# MCXN947_cm33_core0 register map
Vendor: nxp.com; File version: 1.0
CPU: CM33 r2p0, little endian, MPU, FPU, VTOR, 3 interrupt priority bits
Registers are 32-bit, read-write, reset 0x0 unless marked. A register's access mark holds for its fields unless they carry their own. Offsets are from the block's base; [hi:lo] are bit positions; {n}, {i} and the like mark numbered series; 'fields as' and 'values as' point back to an identical list.

## ENET0 (part 2 of 2) — ENET
Base 0x40100000
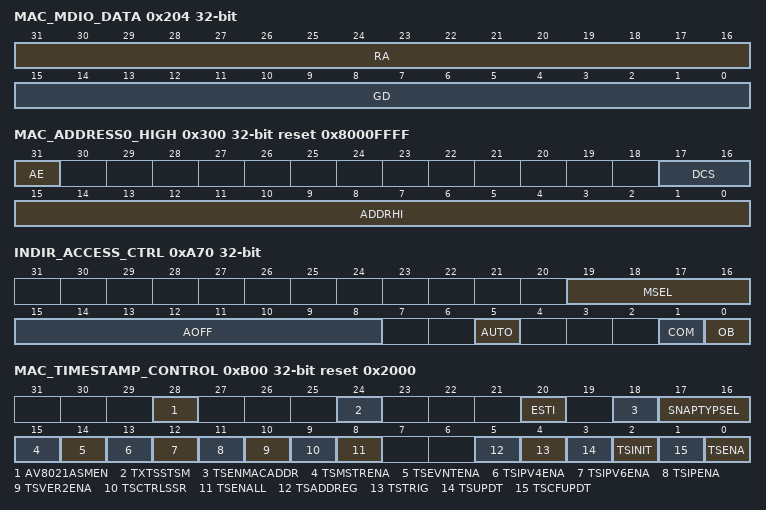
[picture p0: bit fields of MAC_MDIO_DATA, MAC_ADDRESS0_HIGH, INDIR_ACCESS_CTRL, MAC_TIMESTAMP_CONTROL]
0x204 MAC_MDIO_DATA
  [31:16] RA — Register Address
  [15:0] GD — GMII Data
0x230 MAC_CSR_SW_CTRL — CSR Software Control
  [0] RCWE — Register Clear on Write 1 Enable
    0=DISABLE (Register Clear on Write 1 is disabled); 1=ENABLE (Register Clear on Write 1 is enabled)
0x300 MAC_ADDRESS0_HIGH reset 0x8000FFFF
  [31] AE ro — Address Enable
    0=DISABLE (INVALID : This bit must be always set to 1); 1=ENABLE (This bit is always set to 1)
  [17:16] DCS — DMA Channel Select
  [15:0] ADDRHI — MAC Address0[47:32]
0x304 MAC_ADDRESS0_LOW reset 0xFFFFFFFF
  [31:0] ADDRLO — MAC Address0[31:0]
0xA70 INDIR_ACCESS_CTRL — Indirect Access Control
  [19:16] MSEL — Mode Select
  [15:8] AOFF — Address Offset
  [5] AUTO — Auto increment
  [1] COM — Command type
    0=WRITE (Write operation); 1=READ (Read operation)
  [0] OB — Operation Busy.
0xA74 INDIR_ACCESS_DATA — Indirect Access Data
  [31:0] DATA — This field contains data to read/write for Indirect address access associated with MAC_Indir_Access_Ctrl
0xB00 MAC_TIMESTAMP_CONTROL reset 0x2000 — Timestamp Control
  [28] AV8021ASMEN — AV 802.
    0=DISABLE (AV 802.1AS Mode is disabled); 1=ENABLE (AV 802.1AS Mode is enabled)
  [24] TXTSSTSM — Transmit Timestamp Status Mode
    0=DISABLE (Transmit Timestamp Status Mode is disabled); 1=ENABLE (Transmit Timestamp Status Mode is enabled)
  [20] ESTI — External System Time Input
    0=DISABLE (External System Time Input is disabled); 1=ENABLE (External System Time Input is enabled)
  [18] TSENMACADDR — Enable MAC Address for PTP Packet Filtering
    0=DISABLE (MAC Address for PTP Packet Filtering is disabled); 1=ENABLE (MAC Address for PTP Packet Filtering is enabled)
  [17:16] SNAPTYPSEL — Select PTP packets for Taking Snapshots
  [15] TSMSTRENA — Enable Snapshot for Messages Relevant to Master
    0=DISABLE (Snapshot for Messages Relevant to Master is disabled); 1=ENABLE (Snapshot for Messages Relevant to Master is enabled)
  [14] TSEVNTENA — Enable Timestamp Snapshot for Event Messages
    0=DISABLE (Timestamp Snapshot for Event Messages is disabled); 1=ENABLE (Timestamp Snapshot for Event Messages is enabled)
  [13] TSIPV4ENA — Enable Processing of PTP Packets Sent over IPv4-UDP
    0=DISABLE (Processing of PTP Packets Sent over IPv4-UDP is disabled); 1=ENABLE (Processing of PTP Packets Sent over IPv4-UDP is enabled)
  [12] TSIPV6ENA — Enable Processing of PTP Packets Sent over IPv6-UDP
    0=DISABLE (Processing of PTP Packets Sent over IPv6-UDP is disabled); 1=ENABLE (Processing of PTP Packets Sent over IPv6-UDP is enabled)
  [11] TSIPENA — Enable Processing of PTP over Ethernet Packets
    0=DISABLE (Processing of PTP over Ethernet Packets is disabled); 1=ENABLE (Processing of PTP over Ethernet Packets is enabled)
  [10] TSVER2ENA — Enable PTP Packet Processing for Version 2 Format
    0=DISABLE (PTP Packet Processing for Version 2 Format is disabled); 1=ENABLE (PTP Packet Processing for Version 2 Format is enabled)
  [9] TSCTRLSSR — Timestamp Digital or Binary Rollover Control
    0=DISABLE (Timestamp Digital or Binary Rollover Control is disabled); 1=ENABLE (Timestamp Digital or Binary Rollover Control is enabled)
  [8] TSENALL — Enable Timestamp for All Packets
    0=DISABLE (Timestamp for All Packets disabled); 1=ENABLE (Timestamp for All Packets enabled)
  [5] TSADDREG — Update Addend Register
    0=DISABLE (Addend Register is not updated); 1=ENABLE (Addend Register is updated)
  [4] TSTRIG — Enable Timestamp Interrupt Trigger
    0=DISABLE (Timestamp Interrupt Trigger is not enabled); 1=ENABLE (Timestamp Interrupt Trigger is enabled)
  [3] TSUPDT — Update Timestamp
    0=DISABLE (Timestamp is not updated); 1=ENABLE (Timestamp is updated)
  [2] TSINIT — Initialize Timestamp
    0=DISABLE (Timestamp is not initialized); 1=ENABLE (Timestamp is initialized)
  [1] TSCFUPDT — Fine or Coarse Timestamp Update
    0=COARSE (Coarse method is used to update system timestamp); 1=FINE (Fine method is used to update system timestamp)
  [0] TSENA — Enable Timestamp
    0=DISABLE (Timestamp is disabled); 1=ENABLE (Timestamp is enabled)
0xB04 MAC_SUB_SECOND_INCREMENT — Subsecond Increment
  [23:16] SNSINC — Sub-nanosecond Increment Value
0xB08 MAC_SYSTEM_TIME_SECONDS ro — System Time Seconds
  [31:0] TSS — Timestamp Second
0xB0C MAC_SYSTEM_TIME_NANOSECONDS ro — System Time Nanoseconds
  [30:0] TSSS — Timestamp Sub Seconds
0xB10 MAC_SYSTEM_TIME_SECONDS_UPDATE — System Time Seconds Update
  [31:0] TSS — Timestamp Seconds
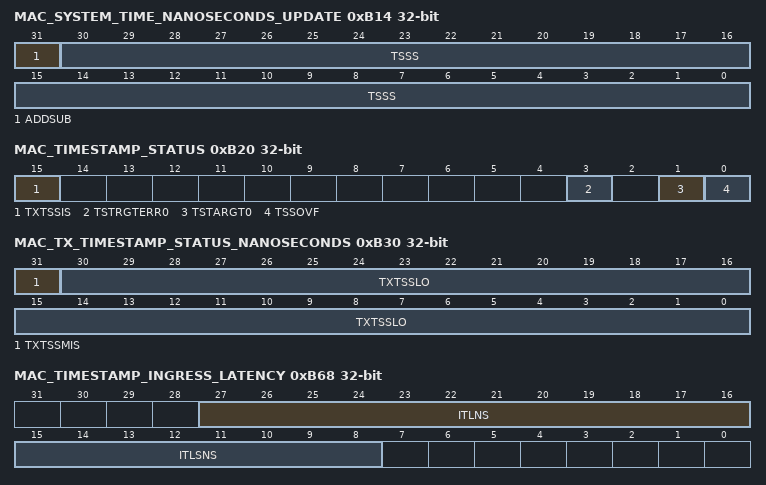
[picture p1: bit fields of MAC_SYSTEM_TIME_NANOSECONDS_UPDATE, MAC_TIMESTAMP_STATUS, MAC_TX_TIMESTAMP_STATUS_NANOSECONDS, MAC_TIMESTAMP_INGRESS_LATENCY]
0xB14 MAC_SYSTEM_TIME_NANOSECONDS_UPDATE — System Time Nanoseconds Update
  [31] ADDSUB — Add or Subtract Time
    0=ADD (Add time); 1=SUB (Subtract time)
  [30:0] TSSS — Timestamp Sub Seconds
0xB18 MAC_TIMESTAMP_ADDEND — Timestamp Addend
  [31:0] TSAR — Timestamp Addend Register
0xB20 MAC_TIMESTAMP_STATUS ro — Timestamp Status
  [15] TXTSSIS — Tx Timestamp Status Interrupt Status
    0=INACTIVE (Tx Timestamp Status Interrupt status not detected); 1=ACTIVE (Tx Timestamp Status Interrupt status detected)
  [3] TSTRGTERR0 — Timestamp Target Time Error
    0=INACTIVE (Timestamp Target Time Error status not detected); 1=ACTIVE (Timestamp Target Time Error status detected)
  [1] TSTARGT0 — Timestamp Target Time Reached
    0=INACTIVE (Timestamp Target Time Reached status not detected); 1=ACTIVE (Timestamp Target Time Reached status detected)
  [0] TSSOVF — Timestamp Seconds Overflow
    0=INACTIVE (Timestamp Seconds Overflow status not detected); 1=ACTIVE (Timestamp Seconds Overflow status detected)
0xB30 MAC_TX_TIMESTAMP_STATUS_NANOSECONDS ro — Transmit Timestamp Status Nanoseconds
  [31] TXTSSMIS
    0=INACTIVE (Transmit Timestamp Status Missed status not detected); 1=ACTIVE (Transmit Timestamp Status Missed status detected)
  [30:0] TXTSSLO — Transmit Timestamp Status Low
0xB34 MAC_TX_TIMESTAMP_STATUS_SECONDS ro — Transmit Timestamp Status Seconds
  [31:0] TXTSSHI — Transmit Timestamp Status High
0xB58 MAC_TIMESTAMP_INGRESS_CORR_NANOSECOND — Timestamp Ingress Correction Nanosecond
  [31:0] TSIC — Timestamp Ingress Correction
0xB5C MAC_TIMESTAMP_EGRESS_CORR_NANOSECOND — Timestamp Egress Correction Nanosecond
  [31:0] TSEC — Timestamp Egress Correction
0xB68 MAC_TIMESTAMP_INGRESS_LATENCY ro — Timestamp Ingress Latency
  [27:16] ITLNS, [15:8] ITLSNS
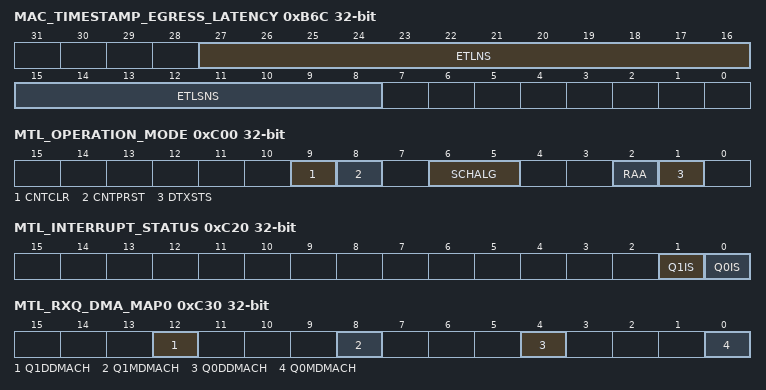
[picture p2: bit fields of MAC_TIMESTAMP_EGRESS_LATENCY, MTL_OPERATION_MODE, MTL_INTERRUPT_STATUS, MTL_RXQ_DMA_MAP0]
0xB6C MAC_TIMESTAMP_EGRESS_LATENCY ro — Timestamp Egress Latency
  [27:16] ETLNS — Egress Timestamp Latency, in nanoseconds
  [15:8] ETLSNS — Egress Timestamp Latency, in sub-nanoseconds
0xB70 MAC_PPS_CONTROL — PPS Control
  [3:0] PPSCTRL_PPSCMD — PPS Output Frequency Control
0xB80 PPS0_TARGET_TIME_SECONDS
  [31:0] TSTRH0 — PPS Target Time Seconds Register
0xB84 PPS0_TARGET_TIME_NANOSECONDS
  [30:0] TTSL0 — Target Time Low for PPS Register
0xC00 MTL_OPERATION_MODE
  [9] CNTCLR — Counters Reset
    0=DISABLE (Counters are not reset); 1=ENABLE (All counters are reset)
  [8] CNTPRST — Counters Preset
    0=DISABLE (Counters Preset is disabled); 1=ENABLE (Counters Preset is enabled)
  [6:5] SCHALG — Tx Scheduling Algorithm
    0=WRR (WRR algorithm); 1=WFQ (WFQ algorithm when DCB feature is selected.Otherwise, Reserved); 2=DWRR (DWRR algorithm when DCB feature is selected.Otherwise, Reserved); 3=SP (Strict priority algorithm)
  [2] RAA — Receive Arbitration Algorithm
    0=SP (Strict priority (SP)); 1=WSP (Weighted Strict Priority (WSP))
  [1] DTXSTS — Drop Transmit Status
    0=DISABLE (Drop Transmit Status is disabled); 1=ENABLE (Drop Transmit Status is enabled)
0xC20 MTL_INTERRUPT_STATUS ro
  [1] Q1IS — Queue 1 Interrupt status
    0=INACTIVE (Queue 1 Interrupt status not detected); 1=ACTIVE (Queue 1 Interrupt status detected)
  [0] Q0IS — Queue 0 Interrupt status
    0=INACTIVE (Queue 0 Interrupt status not detected); 1=ACTIVE (Queue 0 Interrupt status detected)
0xC30 MTL_RXQ_DMA_MAP0 — Receive Queue and DMA Channel Mapping 0
  [12] Q1DDMACH — Queue 1 Enabled for DA-based DMA Channel Selection
    0=DISABLE (Queue 1 disabled for DA-based DMA Channel Selection); 1=ENABLE (Queue 1 enabled for DA-based DMA Channel Selection)
  [8] Q1MDMACH — Queue 1 Mapped to DMA Channel
  [4] Q0DDMACH — Queue 0 Enabled for DA-based DMA Channel Selection
    0=DISABLE (Queue 0 disabled for DA-based DMA Channel Selection); 1=ENABLE (Queue 0 enabled for DA-based DMA Channel Selection)
  [0] Q0MDMACH — Queue 0 Mapped to DMA Channel
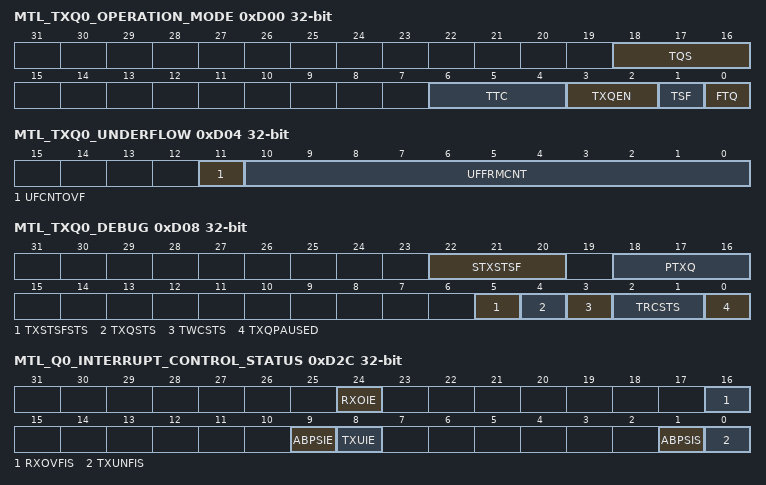
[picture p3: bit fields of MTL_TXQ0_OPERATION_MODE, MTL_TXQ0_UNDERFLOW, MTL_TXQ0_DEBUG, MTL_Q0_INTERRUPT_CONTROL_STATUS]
0xD00 MTL_TXQ0_OPERATION_MODE — Queue 0 Transmit Operation Mode
  [18:16] TQS — Transmit Queue Size
  [6:4] TTC — Transmit Threshold Control
    0=M_32BYTES (32); 1=M_64BYTES (64); 2=M_96BYTES (96); 3=M_128BYTES (128); 4=M_192BYTES (192); 5=M_256BYTES (256); 6=M_384BYTES (384); 7=M_512BYTES (512)
  [3:2] TXQEN — Transmit Queue Enable
    0=DISABLE (Not enabled); 1=EN_IF_AV (Enable in AV mode (Reserved in non-AV)); 2=ENABLE (Enabled)
  [1] TSF — Transmit Store and Forward
    0=DISABLE (Transmit Store and Forward is disabled); 1=ENABLE (Transmit Store and Forward is enabled)
  [0] FTQ — Flush Transmit Queue
    0=DISABLE (Flush Transmit Queue is disabled); 1=ENABLE (Flush Transmit Queue is enabled)
0xD04 MTL_TXQ0_UNDERFLOW ro — Queue 0 Underflow Counter
  [11] UFCNTOVF — Overflow Bit for Underflow Packet Counter
    0=INACTIVE (Overflow not detected for Underflow Packet Counter); 1=ACTIVE (Overflow detected for Underflow Packet Counter)
  [10:0] UFFRMCNT — Underflow Packet Counter
0xD08 MTL_TXQ0_DEBUG ro — Queue 0 Transmit Debug
  [22:20] STXSTSF — Number of Status Words in Tx Status FIFO of Queue
  [18:16] PTXQ — Number of Packets in the Transmit Queue
  [5] TXSTSFSTS — MTL Tx Status FIFO Full Status
    0=INACTIVE (MTL Tx Status FIFO Full status is not detected); 1=ACTIVE (MTL Tx Status FIFO Full status is detected)
  [4] TXQSTS — MTL Tx Queue Not Empty Status
    0=INACTIVE (MTL Tx Queue Not Empty status is not detected); 1=ACTIVE (MTL Tx Queue Not Empty status is detected)
  [3] TWCSTS — MTL Tx Queue Write Controller Status
    0=INACTIVE (MTL Tx Queue Write Controller status is not detected); 1=ACTIVE (MTL Tx Queue Write Controller status is detected)
  [2:1] TRCSTS — MTL Tx Queue Read Controller Status
    0=IDLE (Idle state); 1=READ (Read state (transferring data to the MAC transmitter)); 2=WAIT (Waiting for pending Tx Status from the MAC transmitter); 3=FLUSH (Flushing the Tx queue because of the Packet Abort request from the MAC)
  [0] TXQPAUSED — Transmit Queue in Pause
    0=INACTIVE (Transmit Queue in Pause status is not detected); 1=ACTIVE (Transmit Queue in Pause status is detected)
0xD14 MTL_TXQ0_ETS_STATUS ro — Queue 0 ETS Status
  [23:0] ABS — Average Bits per Slot
0xD18 MTL_TXQ0_QUANTUM_WEIGHT — Queue 0 Quantum or Weights
  [20:0] ISCQW — Quantum or Weights
0xD2C MTL_Q0_INTERRUPT_CONTROL_STATUS — Queue 0 Interrupt Control Status
  [24] RXOIE — Receive Queue Overflow Interrupt Enable
    0=DISABLE (Receive Queue Overflow Interrupt is disabled); 1=ENABLE (Receive Queue Overflow Interrupt is enabled)
  [16] RXOVFIS — Receive Queue Overflow Interrupt Status
    0=INACTIVE (Receive Queue Overflow Interrupt Status not detected); 1=ACTIVE (Receive Queue Overflow Interrupt Status detected)
  [9] ABPSIE — Average Bits Per Slot Interrupt Enable
    0=DISABLE (Average Bits Per Slot Interrupt is disabled); 1=ENABLE (Average Bits Per Slot Interrupt is enabled)
  [8] TXUIE — Transmit Queue Underflow Interrupt Enable
    0=DISABLE (Transmit Queue Underflow Interrupt Status is disabled); 1=ENABLE (Transmit Queue Underflow Interrupt Status is enabled)
  [1] ABPSIS — Average Bits Per Slot Interrupt Status
    0=INACTIVE (Average Bits Per Slot Interrupt Status not detected); 1=ACTIVE (Average Bits Per Slot Interrupt Status detected)
  [0] TXUNFIS — Transmit Queue Underflow Interrupt Status
    0=INACTIVE (Transmit Queue Underflow Interrupt Status not detected); 1=ACTIVE (Transmit Queue Underflow Interrupt Status detected)
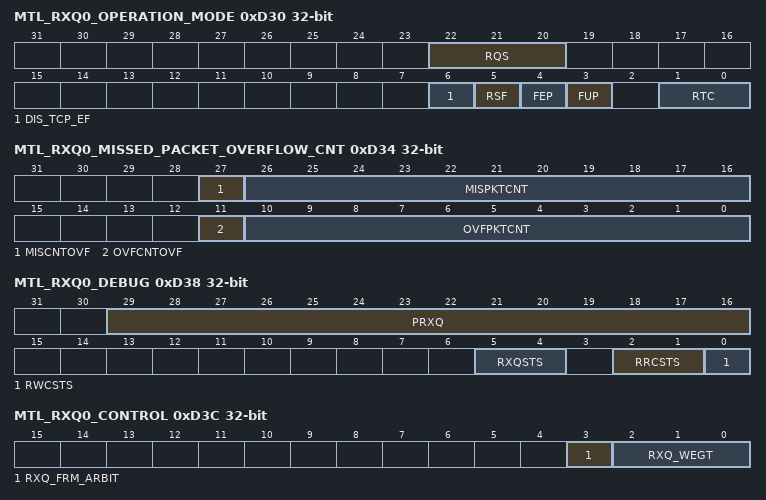
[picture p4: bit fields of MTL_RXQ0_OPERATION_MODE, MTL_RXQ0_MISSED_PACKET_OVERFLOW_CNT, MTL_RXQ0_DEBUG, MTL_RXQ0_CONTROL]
0xD30 MTL_RXQ0_OPERATION_MODE — Queue 0 Receive Operation Mode
  [22:20] RQS — Receive Queue Size
  [6] DIS_TCP_EF — Disable Dropping of TCP/IP Checksum Error Packets
    0=ENABLE (Dropping of TCP/IP Checksum Error Packets is enabled); 1=DISABLE (Dropping of TCP/IP Checksum Error Packets is disabled)
  [5] RSF — Receive Queue Store and Forward
    0=DISABLE (Receive Queue Store and Forward is disabled); 1=ENABLE (Receive Queue Store and Forward is enabled)
  [4] FEP — Forward Error Packets
    0=DISABLE (Forward Error Packets is disabled); 1=ENABLE (Forward Error Packets is enabled)
  [3] FUP — Forward Undersized Good Packets
    0=DISABLE (Forward Undersized Good Packets is disabled); 1=ENABLE (Forward Undersized Good Packets is enabled)
  [1:0] RTC — Receive Queue Threshold Control
    0=M_64BYTE (64); 1=M_32BYTE (32); 2=M_96BYTE (96); 3=M_128BYTE (128)
0xD34 MTL_RXQ0_MISSED_PACKET_OVERFLOW_CNT ro — Queue 0 Missed Packet and Overflow Counter
  [27] MISCNTOVF — Missed Packet Counter Overflow Bit
    0=INACTIVE (Missed Packet Counter overflow not detected); 1=ACTIVE (Missed Packet Counter overflow detected)
  [26:16] MISPKTCNT — Missed Packet Counter
  [11] OVFCNTOVF — Overflow Counter Overflow Bit
    0=INACTIVE (Overflow Counter overflow not detected); 1=ACTIVE (Overflow Counter overflow detected)
  [10:0] OVFPKTCNT — Overflow Packet Counter
0xD38 MTL_RXQ0_DEBUG ro — Queue 0 Receive Debug
  [29:16] PRXQ — Number of Packets in Receive Queue
  [5:4] RXQSTS — MTL Rx Queue Fill-Level Status
    0=EMPTY (Rx Queue empty); 1=BLW_THR (Rx Queue fill-level below flow-control deactivate threshold); 2=ABV_THR (Rx Queue fill-level above flow-control activate threshold); 3=FULL (Rx Queue full)
  [2:1] RRCSTS — MTL Rx Queue Read Controller State
    0=IDLE (Idle state); 1=READ_DATA (Reading packet data); 2=READ_STS (Reading packet status (or timestamp)); 3=FLUSH (Flushing the packet data and status)
  [0] RWCSTS — MTL Rx Queue Write Controller Active Status
    0=INACTIVE (MTL Rx Queue Write Controller Active Status not detected); 1=ACTIVE (MTL Rx Queue Write Controller Active Status detected)
0xD3C MTL_RXQ0_CONTROL — Queue 0 Receive Control
  [3] RXQ_FRM_ARBIT — Receive Queue Packet Arbitration
    0=DISABLE (Receive Queue Packet Arbitration is disabled); 1=ENABLE (Receive Queue Packet Arbitration is enabled)
  [2:0] RXQ_WEGT — Receive Queue Weight
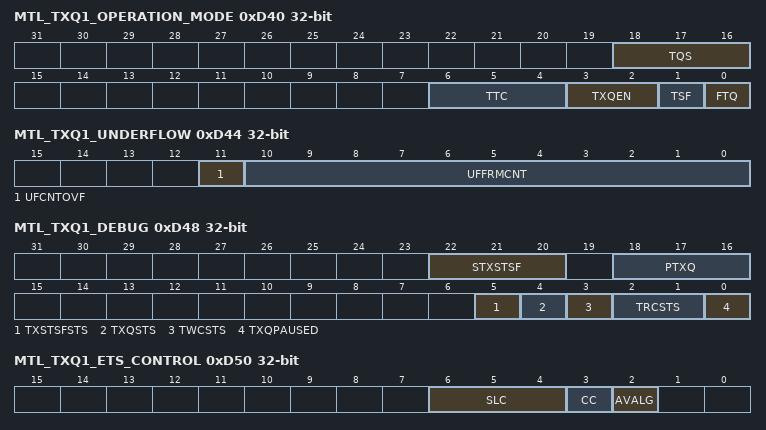
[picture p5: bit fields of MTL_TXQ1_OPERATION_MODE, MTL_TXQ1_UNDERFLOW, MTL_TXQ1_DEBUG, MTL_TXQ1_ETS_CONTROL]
0xD40 MTL_TXQ1_OPERATION_MODE — Queue 1 Transmit Operation Mode
  fields as MTL_TXQ0_OPERATION_MODE
0xD44 MTL_TXQ1_UNDERFLOW ro — Queue 1 Underflow Counter
  fields as MTL_TXQ0_UNDERFLOW
0xD48 MTL_TXQ1_DEBUG ro — Queue 1 Transmit Debug
  fields as MTL_TXQ0_DEBUG
0xD50 MTL_TXQ1_ETS_CONTROL — Queue 1 ETS Control
  [6:4] SLC — Slot Count
    0=M_1_SLOT (1 slot); 1=M_2_SLOT (2 slots); 2=M_4_SLOT (4 slots); 3=M_8_SLOT (8 slots); 4=M_16_SLOT (16 slots)
  [3] CC — Credit Control
    0=DISABLE (Credit Control is disabled); 1=ENABLE (Credit Control is enabled)
  [2] AVALG — AV Algorithm
    0=DISABLE (CBS Algorithm is disabled); 1=ENABLE (CBS Algorithm is enabled)
0xD54 MTL_TXQ1_ETS_STATUS ro — Queue 1 ETS Status
  [23:0] ABS — Average Bits per Slot
0xD58 MTL_TXQ1_QUANTUM_WEIGHT — Queue 1 idleSlopeCredit, Quantum or Weights
  [20:0] ISCQW — idleSlopeCredit, Quantum or Weights
0xD5C MTL_TXQ1_SENDSLOPECREDIT — Queue 1 sendSlopeCredit
  [13:0] SSC — sendSlopeCredit Value
0xD60 MTL_TXQ1_HICREDIT — Queue 1 hiCredit
  [28:0] HC — hiCredit Value
0xD64 MTL_TXQ1_LOCREDIT — Queue 1 loCredit
  [28:0] LC — loCredit Value
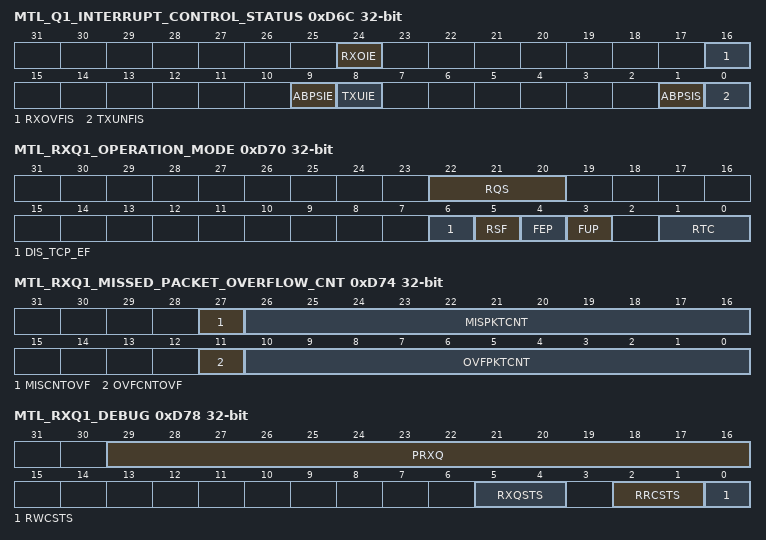
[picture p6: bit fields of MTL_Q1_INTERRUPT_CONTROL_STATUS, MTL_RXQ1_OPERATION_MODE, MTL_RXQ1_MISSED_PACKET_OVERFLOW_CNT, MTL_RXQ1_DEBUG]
0xD6C MTL_Q1_INTERRUPT_CONTROL_STATUS — Queue 1 Interrupt Control Status
  fields as MTL_Q0_INTERRUPT_CONTROL_STATUS
0xD70 MTL_RXQ1_OPERATION_MODE — Queue 1 Receive Operation Mode
  fields as MTL_RXQ0_OPERATION_MODE
0xD74 MTL_RXQ1_MISSED_PACKET_OVERFLOW_CNT ro — Queue 1 Missed Packet and Overflow Counter
  fields as MTL_RXQ0_MISSED_PACKET_OVERFLOW_CNT
0xD78 MTL_RXQ1_DEBUG ro — Queue 1 Receive Debug
  fields as MTL_RXQ0_DEBUG
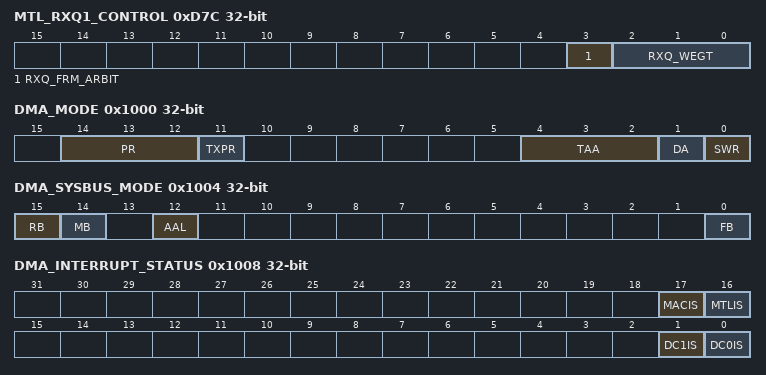
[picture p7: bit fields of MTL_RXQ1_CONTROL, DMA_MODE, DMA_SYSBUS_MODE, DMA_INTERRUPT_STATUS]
0xD7C MTL_RXQ1_CONTROL — Queue 1 Receive Control
  fields as MTL_RXQ0_CONTROL
0x1000 DMA_MODE — DMA Bus Mode
  [14:12] PR — Priority Ratio
    {v}=R_{v+1}_1 (The priority ratio is {v+1}:1) (v=0..7)
  [11] TXPR — Transmit Priority
    0=DISABLE (Transmit Priority is disabled); 1=ENABLE (Transmit Priority is enabled)
  [4:2] TAA — Transmit Arbitration Algorithm
    0=FP (Fixed priority); 1=WSP (Weighted Strict Priority (WSP)); 2=WRR (Weighted Round-Robin (WRR))
  [1] DA — DMA Tx or Rx Arbitration Scheme
    0=WRR (Weighted Round-Robin with Rx:Tx or Tx:Rx); 1=FP (Fixed Priority)
  [0] SWR — Software Reset
    0=DISABLE (Software Reset is disabled); 1=ENABLE (Software Reset is enabled)
0x1004 DMA_SYSBUS_MODE — DMA System Bus Mode
  [15] RB — Rebuild INCRx Burst
    0=DISABLE (Rebuild INCRx Burst is disabled); 1=ENABLE (Rebuild INCRx Burst is enabled)
  [14] MB — Mixed Burst
    0=DISABLE (Mixed Burst is disabled); 1=ENABLE (Mixed Burst is enabled)
  [12] AAL — Address-Aligned Beats
    0=DISABLE (Address-Aligned Beats is disabled); 1=ENABLE (Address-Aligned Beats is enabled)
  [0] FB — Fixed Burst Length
    0=DISABLE (Fixed Burst Length is disabled); 1=ENABLE (Fixed Burst Length is enabled)
0x1008 DMA_INTERRUPT_STATUS ro
  [17] MACIS — MAC Interrupt Status
    0=INACTIVE (MAC Interrupt Status not detected); 1=ACTIVE (MAC Interrupt Status detected)
  [16] MTLIS — MTL Interrupt Status
    0=INACTIVE (MTL Interrupt Status not detected); 1=ACTIVE (MTL Interrupt Status detected)
  [1] DC1IS — DMA Channel 1 Interrupt Status
    0=INACTIVE (DMA Channel 1 Interrupt Status not detected); 1=ACTIVE (DMA Channel 1 Interrupt Status detected)
  [0] DC0IS — DMA Channel 0 Interrupt Status
    0=INACTIVE (DMA Channel 0 Interrupt Status not detected); 1=ACTIVE (DMA Channel 0 Interrupt Status detected)
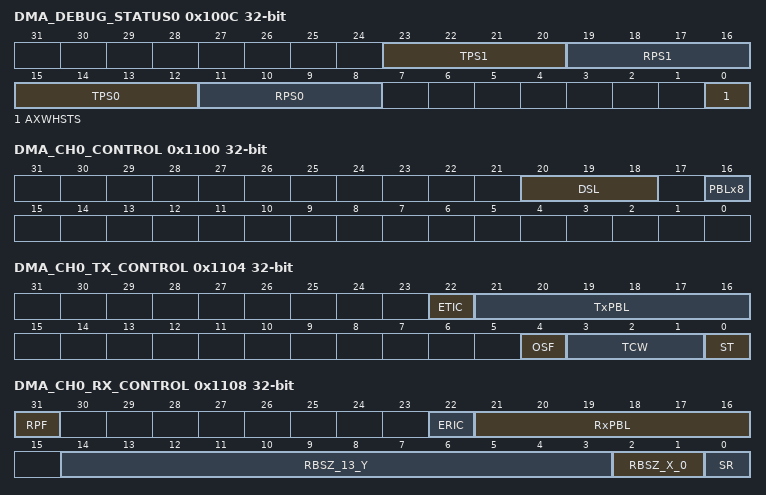
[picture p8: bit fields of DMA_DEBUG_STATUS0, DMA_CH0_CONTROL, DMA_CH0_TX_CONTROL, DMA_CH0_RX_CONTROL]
0x100C DMA_DEBUG_STATUS0 ro
  [23:20] TPS1 — DMA Channel 1 Transmit Process State
    0=STOP (Stopped (Reset or Stop Transmit Command issued)); 1=RUN_FTTD (Running (Fetching Tx Transfer Descriptor)); 2=RUN_WS (Running (Waiting for status)); 3=RUN_RDS (Running (Reading Data from system memory buffer and queuing it to the Tx buffer (Tx FIFO))); 4=TSTMP_WS (Timestamp write state); 6=SUSPND (Suspended (Tx Descriptor Unavailable or Tx Buffer Underflow)); 7=RUN_CTD (Running (Closing Tx Descriptor))
  [19:16] RPS1 — DMA Channel 1 Receive Process State
    0=STOP (Stopped (Reset or Stop Receive Command issued)); 1=RUN_FRTD (Running (Fetching Rx Transfer Descriptor)); 3=RUN_WRP (Running (Waiting for Rx packet)); 4=SUSPND (Suspended (Rx Descriptor Unavailable)); 5=RUN_CRD (Running (Closing the Rx Descriptor)); 6=TSTMP (Timestamp write state); 7=RUN_TRP (Running (Transferring the received packet data from the Rx buffer to the system memory))
  [15:12] TPS0 — DMA Channel 0 Transmit Process State
    values as TPS1
  [11:8] RPS0 — DMA Channel 0 Receive Process State
    values as RPS1
  [0] AXWHSTS — AHB Master Status
    0=INACTIVE (AXI Master Write Channel or AHB Master Status not detected); 1=ACTIVE (AXI Master Write Channel or AHB Master Status detected)
0x1100 DMA_CH0_CONTROL — DMA Channel 0 Control
  [20:18] DSL — Descriptor Skip Length
  [16] PBLx8 — 8xPBL mode
    0=DISABLE (8xPBL mode is disabled); 1=ENABLE (8xPBL mode is enabled)
0x1104 DMA_CH0_TX_CONTROL — DMA Channel 0 Transmit Control
  [22] ETIC — Early Transmit Interrupt Control
    0=DISABLE (Early Transmit Interrupt is disabled); 1=ENABLE (Early Transmit Interrupt is enabled)
  [21:16] TxPBL — Transmit Programmable Burst Length
  [4] OSF — Operate on Second Packet
    0=DISABLE (Operate on Second Packet disabled); 1=ENABLE (Operate on Second Packet enabled)
  [3:1] TCW — Transmit Channel Weight
  [0] ST — Start or Stop Transmission Command
    0=STOP (Stop Transmission Command); 1=START (Start Transmission Command)
0x1108 DMA_CH0_RX_CONTROL — DMA Channel 0 Receive Control
  [31] RPF — Rx Packet Flush.
    0=DISABLE (Rx Packet Flush is disabled); 1=ENABLE (Rx Packet Flush is enabled)
  [22] ERIC — Early Receive Interrupt Control
    0=DISABLE (Early Receive Interrupt is disabled); 1=ENABLE (Early Receive Interrupt is enabled)
  [21:16] RxPBL — Receive Programmable Burst Length
  [14:3] RBSZ_13_Y — Receive Buffer size High
  [2:1] RBSZ_X_0 ro — Receive Buffer size Low
  [0] SR — Start or Stop Receive
    0=STOP (Stop Receive); 1=START (Start Receive)
0x1114 DMA_CH0_TXDESC_LIST_ADDRESS — Channel 0 Tx Descriptor List Address register
  [31:2] TDESLA — Start of Transmit List
0x111C DMA_CH0_RXDESC_LIST_ADDRESS — Channel 0 Rx Descriptor List Address register
  [31:2] RDESLA — Start of Receive List
0x1120 DMA_CH0_TXDESC_TAIL_POINTER — Channel 0 Tx Descriptor Tail Pointer
  [31:2] TDTP — Transmit Descriptor Tail Pointer
0x1128 DMA_CH0_RXDESC_TAIL_POINTER — Channel 0 Rx Descriptor Tail Pointer
  [31:2] RDTP — Receive Descriptor Tail Pointer
0x112C DMA_CH0_TXDESC_RING_LENGTH — Channel 0 Tx Descriptor Ring Length
  [9:0] TDRL — Transmit Descriptor Ring Length
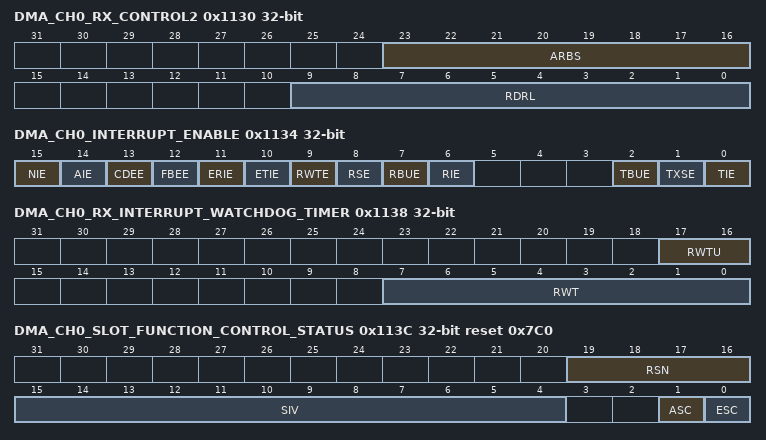
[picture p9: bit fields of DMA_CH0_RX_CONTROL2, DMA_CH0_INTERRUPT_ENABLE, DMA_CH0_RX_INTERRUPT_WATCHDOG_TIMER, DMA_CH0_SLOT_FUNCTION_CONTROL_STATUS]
0x1130 DMA_CH0_RX_CONTROL2 — Channeli Receive Control
  [23:16] ARBS — Alternate Receive Buffer Size
  [9:0] RDRL — Receive Descriptor Ring Length
0x1134 DMA_CH0_INTERRUPT_ENABLE — The Channeli Interrupt Enable register enables the interrupts reported by the Status register.
  [15] NIE — Normal Interrupt Summary Enable
    0=DISABLE (Normal Interrupt Summary is disabled); 1=ENABLE (Normal Interrupt Summary is enabled)
  [14] AIE — Abnormal Interrupt Summary Enable
    0=DISABLE (Abnormal Interrupt Summary is disabled); 1=ENABLE (Abnormal Interrupt Summary is enabled)
  [13] CDEE — Context Descriptor Error Enable
    0=DISABLE (Context Descriptor Error is disabled); 1=ENABLE (Context Descriptor Error is enabled)
  [12] FBEE — Fatal Bus Error Enable
    0=DISABLE (Fatal Bus Error is disabled); 1=ENABLE (Fatal Bus Error is enabled)
  [11] ERIE — Early Receive Interrupt Enable
    values as DMA_CH0_RX_CONTROL.ERIC
  [10] ETIE — Early Transmit Interrupt Enable
    values as DMA_CH0_TX_CONTROL.ETIC
  [9] RWTE — Receive Watchdog Timeout Enable
    0=DISABLE (Receive Watchdog Timeout is disabled); 1=ENABLE (Receive Watchdog Timeout is enabled)
  [8] RSE — Receive Stopped Enable
    0=DISABLE (Receive Stopped is disabled); 1=ENABLE (Receive Stopped is enabled)
  [7] RBUE — Receive Buffer Unavailable Enable
    0=DISABLE (Receive Buffer Unavailable is disabled); 1=ENABLE (Receive Buffer Unavailable is enabled)
  [6] RIE — Receive Interrupt Enable
    0=DISABLE (Receive Interrupt is disabled); 1=ENABLE (Receive Interrupt is enabled)
  [2] TBUE — Transmit Buffer Unavailable Enable
    0=DISABLE (Transmit Buffer Unavailable is disabled); 1=ENABLE (Transmit Buffer Unavailable is enabled)
  [1] TXSE — Transmit Stopped Enable
    0=DISABLE (Transmit Stopped is disabled); 1=ENABLE (Transmit Stopped is enabled)
  [0] TIE — Transmit Interrupt Enable
    0=DISABLE (Transmit Interrupt is disabled); 1=ENABLE (Transmit Interrupt is enabled)
0x1138 DMA_CH0_RX_INTERRUPT_WATCHDOG_TIMER — Channel 0 Receive Interrupt Watchdog Timer
  [17:16] RWTU — Receive Interrupt Watchdog Timer Count Units
  [7:0] RWT — Receive Interrupt Watchdog Timer Count
0x113C DMA_CH0_SLOT_FUNCTION_CONTROL_STATUS reset 0x7C0 — Channel 0 Slot Function Control and Status
  [19:16] RSN ro — Reference Slot Number
  [15:4] SIV — Slot Interval Value
  [1] ASC — Advance Slot Check
    0=DISABLE (Advance Slot Check is disabled); 1=ENABLE (Advance Slot Check is enabled)
  [0] ESC — Enable Slot Comparison
    0=DISABLE (Slot Comparison is disabled); 1=ENABLE (Slot Comparison is enabled)
0x1144 DMA_CH0_CURRENT_APP_TXDESC ro — Channel 0 Current Application Transmit Descriptor
  [31:0] CURTDESAPTR — Application Transmit Descriptor Address Pointer
0x114C DMA_CH0_CURRENT_APP_RXDESC ro — Channel 0 Current Application Receive Descriptor
  [31:0] CURRDESAPTR — Application Receive Descriptor Address Pointer
0x1154 DMA_CH0_CURRENT_APP_TXBUFFER ro — Channel 0 Current Application Transmit Buffer Address
  [31:0] CURTBUFAPTR — Application Transmit Buffer Address Pointer
0x115C DMA_CH0_CURRENT_APP_RXBUFFER ro — Channel 0 Current Application Receive Buffer Address
  [31:0] CURRBUFAPTR — Application Receive Buffer Address Pointer
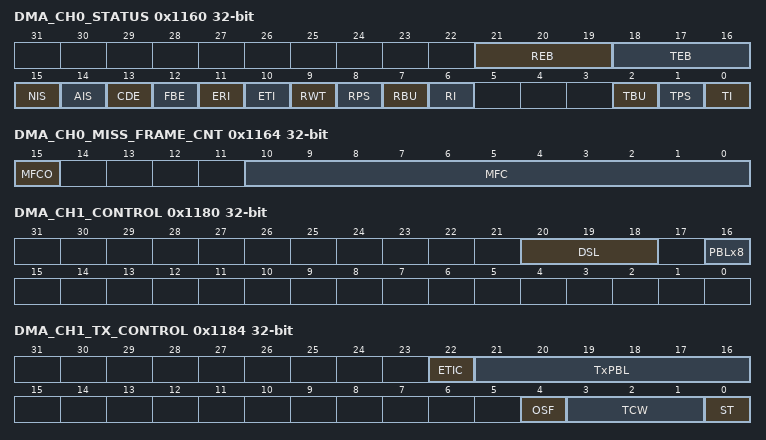
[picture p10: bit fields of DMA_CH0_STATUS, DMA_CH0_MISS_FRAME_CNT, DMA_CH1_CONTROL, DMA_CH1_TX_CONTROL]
0x1160 DMA_CH0_STATUS — DMA Channel 0 Status
  [21:19] REB ro — Rx DMA Error Bits
  [18:16] TEB ro — Tx DMA Error Bits
  [15] NIS — Normal Interrupt Summary
    0=INACTIVE (Normal Interrupt Summary status not detected); 1=ACTIVE (Normal Interrupt Summary status detected)
  [14] AIS — Abnormal Interrupt Summary
    0=INACTIVE (Abnormal Interrupt Summary status not detected); 1=ACTIVE (Abnormal Interrupt Summary status detected)
  [13] CDE — Context Descriptor Error
    0=INACTIVE (Context Descriptor Error status not detected); 1=ACTIVE (Context Descriptor Error status detected)
  [12] FBE — Fatal Bus Error
    0=INACTIVE (Fatal Bus Error status not detected); 1=ACTIVE (Fatal Bus Error status detected)
  [11] ERI — Early Receive Interrupt
    0=INACTIVE (Early Receive Interrupt status not detected); 1=ACTIVE (Early Receive Interrupt status detected)
  [10] ETI — Early Transmit Interrupt
    0=INACTIVE (Early Transmit Interrupt status not detected); 1=ACTIVE (Early Transmit Interrupt status detected)
  [9] RWT — Receive Watchdog Timeout
    0=INACTIVE (Receive Watchdog Timeout status not detected); 1=ACTIVE (Receive Watchdog Timeout status detected)
  [8] RPS — Receive Process Stopped
    0=INACTIVE (Receive Process Stopped status not detected); 1=ACTIVE (Receive Process Stopped status detected)
  [7] RBU — Receive Buffer Unavailable
    0=INACTIVE (Receive Buffer Unavailable status not detected); 1=ACTIVE (Receive Buffer Unavailable status detected)
  [6] RI — Receive Interrupt
    0=INACTIVE (Receive Interrupt status not detected); 1=ACTIVE (Receive Interrupt status detected)
  [2] TBU — Transmit Buffer Unavailable
    0=INACTIVE (Transmit Buffer Unavailable status not detected); 1=ACTIVE (Transmit Buffer Unavailable status detected)
  [1] TPS — Transmit Process Stopped
    0=INACTIVE (Transmit Process Stopped status not detected); 1=ACTIVE (Transmit Process Stopped status detected)
  [0] TI — Transmit Interrupt
    0=INACTIVE (Transmit Interrupt status not detected); 1=ACTIVE (Transmit Interrupt status detected)
0x1164 DMA_CH0_MISS_FRAME_CNT ro — Channel 0 Missed Frame Counter
  [15] MFCO — Overflow status of the MFC Counter
    0=INACTIVE (Miss Frame Counter overflow not occurred); 1=ACTIVE (Miss Frame Counter overflow occurred)
  [10:0] MFC — Dropped Packet Counters
0x116C DMA_CH0_RX_ERI_CNT ro — Channel 0 Receive ERI Counter
  [11:0] ECNT — ERI Counter
0x1180 DMA_CH1_CONTROL — DMA Channel 1 Control
  fields as DMA_CH0_CONTROL
0x1184 DMA_CH1_TX_CONTROL — DMA Channel 1 Transmit Control
  fields as DMA_CH0_TX_CONTROL
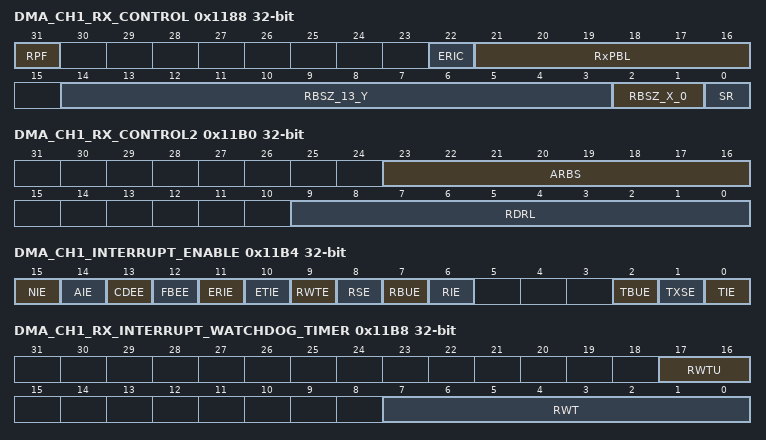
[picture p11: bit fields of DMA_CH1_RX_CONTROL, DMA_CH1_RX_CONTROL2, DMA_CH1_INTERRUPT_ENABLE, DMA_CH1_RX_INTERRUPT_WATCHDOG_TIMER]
0x1188 DMA_CH1_RX_CONTROL — DMA Channel 1 Receive Control
  fields as DMA_CH0_RX_CONTROL
0x1194 DMA_CH1_TXDESC_LIST_ADDRESS — Channel 1 Tx Descriptor List Address
  [31:2] TDESLA — Start of Transmit List
0x119C DMA_CH1_RXDESC_LIST_ADDRESS — Channel 1 Rx Descriptor List Address
  [31:2] RDESLA — Start of Receive List
0x11A0 DMA_CH1_TXDESC_TAIL_POINTER — Channel 1 Tx Descriptor Tail Pointer
  [31:2] TDTP — Transmit Descriptor Tail Pointer
0x11A8 DMA_CH1_RXDESC_TAIL_POINTER — Channel 1 Rx Descriptor Tail Pointer
  [31:2] RDTP — Receive Descriptor Tail Pointer
0x11AC DMA_CH1_TXDESC_RING_LENGTH — Channel 1 Tx Descriptor Ring Length
  [9:0] TDRL — Transmit Descriptor Ring Length
0x11B0 DMA_CH1_RX_CONTROL2 — DMA Channel 1 Receive Control
  fields as DMA_CH0_RX_CONTROL2
0x11B4 DMA_CH1_INTERRUPT_ENABLE — Channel 1 Interrupt Enable
  fields as DMA_CH0_INTERRUPT_ENABLE
0x11B8 DMA_CH1_RX_INTERRUPT_WATCHDOG_TIMER — Channel 1 Receive Interrupt Watchdog Timer
  fields as DMA_CH0_RX_INTERRUPT_WATCHDOG_TIMER
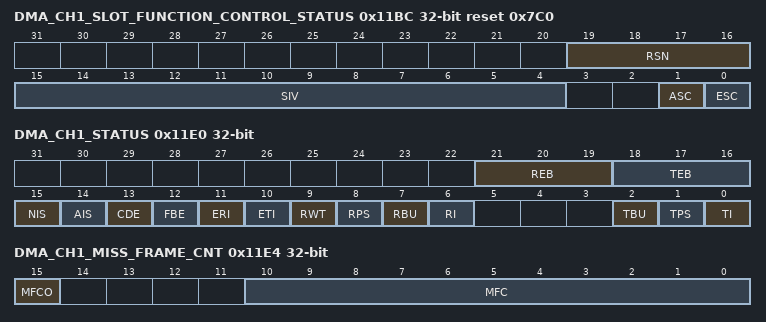
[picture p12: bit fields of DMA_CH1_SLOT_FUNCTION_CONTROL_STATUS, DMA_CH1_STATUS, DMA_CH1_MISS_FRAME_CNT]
0x11BC DMA_CH1_SLOT_FUNCTION_CONTROL_STATUS reset 0x7C0 — Channel 1 Slot Function Control and Status
  fields as DMA_CH0_SLOT_FUNCTION_CONTROL_STATUS
0x11C4 DMA_CH1_CURRENT_APP_TXDESC ro — Channel 1 Current Application Transmit Descriptor
  [31:0] CURTDESAPTR — Application Transmit Descriptor Address Pointer
0x11CC DMA_CH1_CURRENT_APP_RXDESC ro — Channel 1 Current Application Receive Descriptor
  [31:0] CURRDESAPTR — Application Receive Descriptor Address Pointer
0x11D4 DMA_CH1_CURRENT_APP_TXBUFFER ro — Channel 1 Current Application Transmit Buffer Address
  [31:0] CURTBUFAPTR — Application Transmit Buffer Address Pointer
0x11DC DMA_CH1_CURRENT_APP_RXBUFFER ro — Channel 1 Current Application Receive Buffer Address
  [31:0] CURRBUFAPTR — Application Receive Buffer Address Pointer
0x11E0 DMA_CH1_STATUS — DMA Channel 1 Status
  fields as DMA_CH0_STATUS
0x11E4 DMA_CH1_MISS_FRAME_CNT ro — Channel 1 Missed Frame Counter
  fields as DMA_CH0_MISS_FRAME_CNT
0x11EC DMA_CH1_RX_ERI_CNT ro — Channel 1 Receive ERI Counter
  [11:0] ECNT — ERI Counter
